# CY8C5888LTI_LP097 register map
File version: 0.1
Registers are 8-bit, read-write, no defined reset value unless marked. A register's access mark holds for its fields unless they carry their own. Offsets are from the block's base; [hi:lo] are bit positions; {n}, {i} and the like mark numbered series; 'fields as' and 'values as' point back to an identical list.

## CONTROL
Base 0x00000000
0x40006479 CONTROL_CONTROL_REG

## UART
Base 0x00000000
0x40006524 RX_UART_RX_ADDRESS1 — RX Address1 Register
0x40006534 RX_UART_RX_ADDRESS2 — RX Address2 Register
0x40006544 RX_UART_RX_DATA — RX Data Register
0x40006548 TX_UART_TX_DATA — TX Data Register
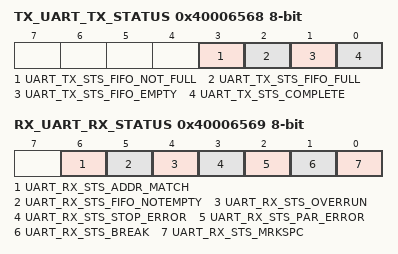
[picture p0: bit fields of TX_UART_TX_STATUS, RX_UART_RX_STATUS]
0x40006568 TX_UART_TX_STATUS — TX status register
  [3] UART_TX_STS_FIFO_NOT_FULL ro, [2] UART_TX_STS_FIFO_FULL ro, [1] UART_TX_STS_FIFO_EMPTY ro, [0] UART_TX_STS_COMPLETE ro
0x40006569 RX_UART_RX_STATUS — RX status register
  [6] UART_RX_STS_ADDR_MATCH ro, [5] UART_RX_STS_FIFO_NOTEMPTY ro, [4] UART_RX_STS_OVERRUN ro, [3] UART_RX_STS_STOP_ERROR ro, [2] UART_RX_STS_PAR_ERROR ro, [1] UART_RX_STS_BREAK ro, [0] UART_RX_STS_MRKSPC ro

## RF_BT_SELECT
Base 0x00000000
0x40006474 RF_BT_SELECT_CONTROL_REG

## QuadDec_M2
Base 0x00000000
0x40006406 QuadDec_M2_Cnt16_COUNTER 16-bit — Counter value
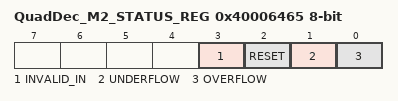
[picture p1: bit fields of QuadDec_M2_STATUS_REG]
0x40006465 QuadDec_M2_STATUS_REG — Quadrature Decoder Status Register
  [3] INVALID_IN ro — Invalid state transition on the A and B inputs
  [2] RESET ro — Counter Reset due index
  [1] UNDERFLOW ro — Counter underflow
  [0] OVERFLOW ro — Counter overflow

## QuadDec_M2_Cnt16
Base 0x00000000; alternate view of QuadDec_M2
0x40006406 QuadDec_M2_Cnt16_COUNTER 16-bit — UDB.A0 - Current Counter Value
0x40006426 QuadDec_M2_Cnt16_PERIOD 16-bit — UDB.D0 - Assigned Period
0x40006436 QuadDec_M2_Cnt16_COMPARE 16-bit — UDB.D1 - Assigned Compare Value
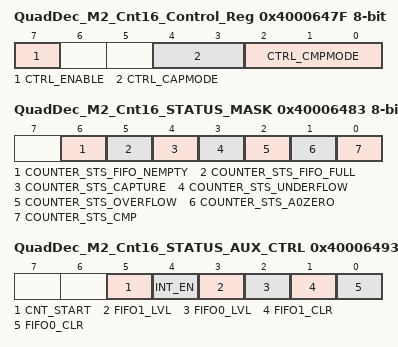
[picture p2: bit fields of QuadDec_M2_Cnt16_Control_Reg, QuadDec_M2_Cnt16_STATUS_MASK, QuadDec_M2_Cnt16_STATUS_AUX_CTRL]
0x4000647F QuadDec_M2_Cnt16_Control_Reg — UDB Control Register - Assigned Control Register Value
  [7] CTRL_ENABLE — Enable Counter
  [4:3] CTRL_CAPMODE — Capture mode
  [2:0] CTRL_CMPMODE — Compare mode
0x40006483 QuadDec_M2_Cnt16_STATUS_MASK — UDB Status bits Interrupt Mask Enable Register
  [6] COUNTER_STS_FIFO_NEMPTY — FIFO Not Empty Status
  [5] COUNTER_STS_FIFO_FULL — FIFO Full Status
  [4] COUNTER_STS_CAPTURE — Capture Status
  [3] COUNTER_STS_UNDERFLOW — Underflow status
  [2] COUNTER_STS_OVERFLOW — Overflow status
  [1] COUNTER_STS_A0ZERO — A0 Zero ouput status
  [0] COUNTER_STS_CMP — Compare output status
0x40006493 QuadDec_M2_Cnt16_STATUS_AUX_CTRL — UDB Auxilliary Control Register
  [5] CNT_START — FIFO0 clear
    0=E_CNT_START0 (Disable counter); 1=E_CNT_START1 (Enable counter)
  [4] INT_EN
    0=E_INT_EN0 (Interrupt disabled); 1=E_INT_EN1 (Interrupt enabled)
  [3] FIFO1_LVL — FIFO level
    0=E_FIFO_LVL_0 (FIFO LVL: input mode: FIFO not full; output mode: FIFO not empty); 1=E_FIFO_LVL_1 (FIFO LVL: input mode: FIFO at least 1/2 empty; output mode: FIFO at least 1/2 full)
  [2] FIFO0_LVL — FIFO level
    values as FIFO1_LVL
  [1] FIFO1_CLR — FIFO1 clear
    0=E_FIFO_CLR_0 (Normal FIFO operation); 1=E_FIFO_CLR_1 (Clear FIFO state)
  [0] FIFO0_CLR — FIFO0 clear
    values as FIFO1_CLR

## QuadDec_M1
Base 0x00000000
0x4000640A QuadDec_M1_Cnt16_COUNTER 16-bit — Counter value
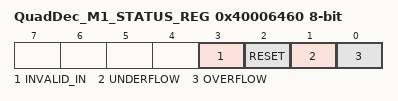
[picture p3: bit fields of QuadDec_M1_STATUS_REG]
0x40006460 QuadDec_M1_STATUS_REG — Quadrature Decoder Status Register
  [3] INVALID_IN ro — Invalid state transition on the A and B inputs
  [2] RESET ro — Counter Reset due index
  [1] UNDERFLOW ro — Counter underflow
  [0] OVERFLOW ro — Counter overflow

## QuadDec_M1_Cnt16
Base 0x00000000; alternate view of QuadDec_M1
0x4000640A QuadDec_M1_Cnt16_COUNTER 16-bit — UDB.A0 - Current Counter Value
0x4000642A QuadDec_M1_Cnt16_PERIOD 16-bit — UDB.D0 - Assigned Period
0x4000643A QuadDec_M1_Cnt16_COMPARE 16-bit — UDB.D1 - Assigned Compare Value
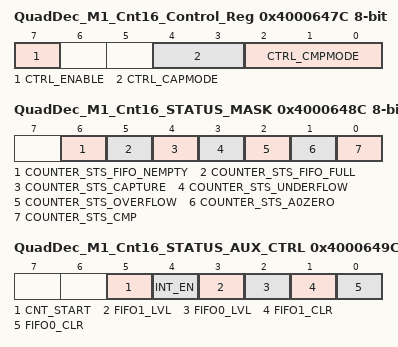
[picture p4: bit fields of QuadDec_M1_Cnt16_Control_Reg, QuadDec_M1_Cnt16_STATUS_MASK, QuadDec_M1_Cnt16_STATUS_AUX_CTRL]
0x4000647C QuadDec_M1_Cnt16_Control_Reg — UDB Control Register - Assigned Control Register Value
  [7] CTRL_ENABLE — Enable Counter
  [4:3] CTRL_CAPMODE — Capture mode
  [2:0] CTRL_CMPMODE — Compare mode
0x4000648C QuadDec_M1_Cnt16_STATUS_MASK — UDB Status bits Interrupt Mask Enable Register
  [6] COUNTER_STS_FIFO_NEMPTY — FIFO Not Empty Status
  [5] COUNTER_STS_FIFO_FULL — FIFO Full Status
  [4] COUNTER_STS_CAPTURE — Capture Status
  [3] COUNTER_STS_UNDERFLOW — Underflow status
  [2] COUNTER_STS_OVERFLOW — Overflow status
  [1] COUNTER_STS_A0ZERO — A0 Zero ouput status
  [0] COUNTER_STS_CMP — Compare output status
0x4000649C QuadDec_M1_Cnt16_STATUS_AUX_CTRL — UDB Auxilliary Control Register
  [5] CNT_START — FIFO0 clear
    0=E_CNT_START0 (Disable counter); 1=E_CNT_START1 (Enable counter)
  [4] INT_EN
    0=E_INT_EN0 (Interrupt disabled); 1=E_INT_EN1 (Interrupt enabled)
  [3] FIFO1_LVL — FIFO level
    0=E_FIFO_LVL_0 (FIFO LVL: input mode: FIFO not full; output mode: FIFO not empty); 1=E_FIFO_LVL_1 (FIFO LVL: input mode: FIFO at least 1/2 empty; output mode: FIFO at least 1/2 full)
  [2] FIFO0_LVL — FIFO level
    values as FIFO1_LVL
  [1] FIFO1_CLR — FIFO1 clear
    0=E_FIFO_CLR_0 (Normal FIFO operation); 1=E_FIFO_CLR_1 (Clear FIFO state)
  [0] FIFO0_CLR — FIFO0 clear
    values as FIFO1_CLR

## Timer_TS
Base 0x00000000
0x400043A3 Timer_TS_GLOBAL_ENABLE — PM.ACT.CFG
  [3:0] en_timer — Enable timer/counters.
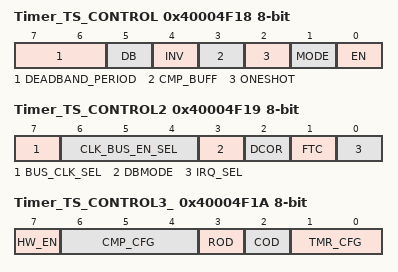
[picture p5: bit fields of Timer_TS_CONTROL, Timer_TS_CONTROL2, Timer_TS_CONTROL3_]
0x40004F18 Timer_TS_CONTROL — TMRx.CFG0
  [7:6] DEADBAND_PERIOD
  [5] DB — Deadband mode--Deadband phases phi1 and phi2 are outputted on CMP and TC output pins respectively.
    0=Timer (CMP and TC are output.); 1=Deadband (PHI1 (instead of CMP) and PHI2 (instead of TC) are output.)
  [4] INV — Invert sense of TIMEREN signal
  [3] CMP_BUFF — Buffer compare register. Compare register updates only on timer terminal count.
  [2] ONESHOT — Timer stops upon reaching stop condition defined by TMR_CFG bits. Can be restarted by asserting TIMER RESET or disabling and re-enabling block.
  [1] MODE — Mode. (0 = Timer; 1 = Comparator)
    0=Timer mode. CNT/CMP register holds timer count value.; 1=Comparator mode. CNT/CMP register holds comparator threshold value.
  [0] EN — Enables timer/comparator.
0x40004F19 Timer_TS_CONTROL2 — TMRx.CFG1
  [7] BUS_CLK_SEL — Bus Clock selection.
  [6:4] CLK_BUS_EN_SEL — Digital Global Clock selection.
  [3] DBMODE — Deadband mode (asynchronous/synchronous). CMP output pin is also affected when not in deadband mode (CFG0.DEADBAND).
  [2] DCOR — Disable Clear on Read (DCOR) of Status Register SR0.
  [1] FTC — First Terminal Count (FTC). Setting this bit forces a single pulse on the TC pin when first enabled.
    0=Disable_FTC (Disable the single cycle pulse, which signifies the timer is starting.); 1=Enable_FTC (Enable the single cycle pulse, which signifies the timer is starting.)
  [0] IRQ_SEL — Irq selection. (0 = raw interrupts; 1 = status register interrupts)
0x40004F1A Timer_TS_CONTROL3_ — TMRx.CFG2
  [7] HW_EN — When set Timer Enable controls counting.
  [6:4] CMP_CFG — Comparator configurations
    0=Equal (Compare Equal); 1=Less_than (Compare Less Than); 2=Less_than_or_equal (Compare Less Than or Equal .); 3=Greater (Compare Greater Than .); 4=Greater_than_or_equal (Compare Greater Than or Equal)
  [3] ROD — Reset On Disable (ROD). Resets internal state of output logic
  [2] COD — Clear On Disable (COD). Clears or gates outputs to zero.
  [1:0] TMR_CFG — Timer configuration (MODE = 0): 000 = Continuous; 001 = Pulsewidth; 010 = Period; 011 = Stop on IRQ
    0=Continuous (Timer runs while EN bit of CFG0 register is set to '1'.); 1=Pulsewidth (Timer runs from positive to negative edge of TIMEREN.); 2=Period (Timer runs from positive to positive edge of TIMEREN.); 3=Irq (Timer runs until IRQ.)
0x40004F1C Timer_TS_PERIOD — TMRx.PER0 - Assigned Period
0x40004F1E Timer_TS_COUNTER — TMRx.CNT_CMP0 - Current Down Counter Value

## ADC_Sensor_SAR — SAR ADC
Base 0x00000000
0x40004616 SAR_TR0 — SAR trim register
{0x40005908+i} SAR_CSR{i} (i=0..6) — SAR status and control register {i}
0x40005B28 SAR_SW0 — SAR Analog Routing Register 0
{0x40005B28+i} SAR_SW{i} (i=2..4) — SAR Analog Routing Register {i}
0x40005B2E SAR_SW6 — SAR Analog Routing Register 6
0x40005B2F SAR_CLK — SAR Clock Selection Register
0x40005BA2 SAR_WRK 16-bit — SAR working register
